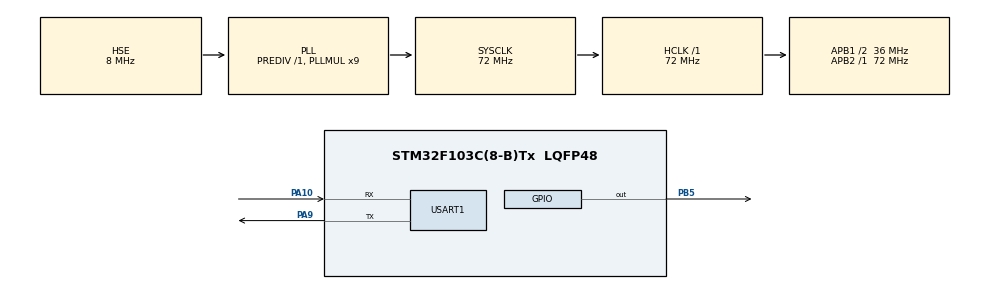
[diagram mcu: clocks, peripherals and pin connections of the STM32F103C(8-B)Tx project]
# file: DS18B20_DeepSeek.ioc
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Mcu.Family=STM32F1
Mcu.Name=STM32F103C(8-B)Tx
Mcu.Package=LQFP48
NVIC.PriorityGroup=NVIC_PRIORITYGROUP_4
PA10.Mode=Asynchronous
PA10.Signal=USART1_RX
PA13.Mode=Serial_Wire
PA13.Signal=SYS_JTMS-SWDIO
PA14.Mode=Serial_Wire
PA14.Signal=SYS_JTCK-SWCLK
PA9.Mode=Asynchronous
PA9.Signal=USART1_TX
PB5.GPIO_ModeDefaultOutputPP=GPIO_MODE_OUTPUT_OD
PB5.GPIO_PuPd=GPIO_NOPULL
PB5.Signal=GPIO_Output
PD0-OSC_IN.Mode=HSE-External-Oscillator
PD0-OSC_IN.Signal=RCC_OSC_IN
PD1-OSC_OUT.Mode=HSE-External-Oscillator
PD1-OSC_OUT.Signal=RCC_OSC_OUT
ProjectManager.HeapSize=0x200
ProjectManager.StackSize=0x400
ProjectManager.TargetToolchain=STM32CubeIDE
RCC.AHBFreq_Value=72000000
RCC.APB1CLKDivider=RCC_HCLK_DIV2
RCC.APB1Freq_Value=36000000
RCC.APB1TimFreq_Value=72000000
RCC.APB2Freq_Value=72000000
RCC.APB2TimFreq_Value=72000000
RCC.HCLKFreq_Value=72000000
RCC.PLLMUL=RCC_PLL_MUL9
RCC.PLLSourceVirtual=RCC_PLLSOURCE_HSE
RCC.SYSCLKFreq_VALUE=72000000
RCC.SYSCLKSource=RCC_SYSCLKSOURCE_PLLCLK
RCC.USBFreq_Value=72000000
USART1.VirtualMode=VM_ASYNC
board=custom

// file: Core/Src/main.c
/* USER CODE BEGIN Header */
/**
  * @file    main.c
  * @brief   Minimal firmware entry: HAL init + cooperative scheduler loop only.
  *
  * @details
  * This project is intentionally wired as a **standalone scheduler**:
  * no application tasks are registered here. USART1 is initialised so you can
  * optionally call scheduler_set_debug_uart() and scheduler_print_status() for
  * diagnostics (see scheduler.h and the guide at the top of scheduler.c).
  *
  * HARDWARE (typical Blue Pill):
  *   - MCU: STM32F103C8
  *   - UART: USART1 (PA9 TX, PA10 RX), 115200 8N1 — pins configured in HAL_UART_MspInit()
  *
  * TIME BASE:
  *   - SysTick drives HAL_GetTick() at 1 ms; the scheduler relies on that (see SCHEDULER_TICK_MS).
  */
/* USER CODE END Header */
#include "main.h"

/* USER CODE BEGIN Includes */
#include "scheduler.h"
/* USER CODE END Includes */

UART_HandleTypeDef huart1;

void SystemClock_Config(void);
static void MX_GPIO_Init(void);
static void MX_USART1_UART_Init(void);
/* USER CODE BEGIN PFP */
void Error_Handler(void);
/* USER CODE END PFP */

int main(void)
{

  /* MCU Configuration--------------------------------------------------------*/

  /* Reset of all peripherals, Initializes the Flash interface and the Systick. */
HAL_Init();

  /* Configure the system clock */
  SystemClock_Config();

  /* Initialize all configured peripherals */
  MX_GPIO_Init();
  MX_USART1_UART_Init();

  /* USER CODE BEGIN 2 */

  scheduler_init();
  /* Optional: enable scheduler_print_status() output on USART1 */
  scheduler_set_debug_uart(&huart1);

  /*
   * -------------------------------------------------------------------------
   * Register your application tasks here (see scheduler.h, section
   * "HOW TO ADD APPLICATION TASKS").
   * Example (commented out — requires your task module):
   *
   *   my_task_init();
   *   if (scheduler_add_task(my_task_run, 100U, TASK_MODE_PERIODIC_T, "MyTask") != SCH_STATUS_OK_T)
   *   {
   *       Error_Handler();
   *   }
   * -------------------------------------------------------------------------
   */

  /* USER CODE END 2 */

  /* Infinite loop */
  /* USER CODE BEGIN WHILE */
  while (1)
  {

      scheduler_run();
    /* USER CODE END WHILE */

  }
}

void SystemClock_Config(void)
{
  RCC_OscInitTypeDef RCC_OscInitStruct = {0};
  RCC_ClkInitTypeDef RCC_ClkInitStruct = {0};

  /** Initializes the RCC Oscillators according to the specified parameters
  * in the RCC_OscInitTypeDef structure.
  */
  RCC_OscInitStruct.OscillatorType = RCC_OSCILLATORTYPE_HSE;
  RCC_OscInitStruct.HSEState = RCC_HSE_ON;
  RCC_OscInitStruct.HSEPredivValue = RCC_HSE_PREDIV_DIV1;
  RCC_OscInitStruct.HSIState = RCC_HSI_ON;
  RCC_OscInitStruct.PLL.PLLState = RCC_PLL_ON;
  RCC_OscInitStruct.PLL.PLLSource = RCC_PLLSOURCE_HSE;
  RCC_OscInitStruct.PLL.PLLMUL = RCC_PLL_MUL9;
  if (HAL_RCC_OscConfig(&RCC_OscInitStruct) != HAL_OK)
  {
    Error_Handler();
  }

  /** Initializes the CPU, AHB and APB buses clocks
  */
  RCC_ClkInitStruct.ClockType = RCC_CLOCKTYPE_HCLK|RCC_CLOCKTYPE_SYSCLK
                              |RCC_CLOCKTYPE_PCLK1|RCC_CLOCKTYPE_PCLK2;
  RCC_ClkInitStruct.SYSCLKSource = RCC_SYSCLKSOURCE_PLLCLK;
  RCC_ClkInitStruct.AHBCLKDivider = RCC_SYSCLK_DIV1;
  RCC_ClkInitStruct.APB1CLKDivider = RCC_HCLK_DIV2;
  RCC_ClkInitStruct.APB2CLKDivider = RCC_HCLK_DIV1;

  if (HAL_RCC_ClockConfig(&RCC_ClkInitStruct, FLASH_LATENCY_2) != HAL_OK)
  {
    Error_Handler();
  }
}

static void MX_USART1_UART_Init(void)
{

  huart1.Instance = USART1;
  huart1.Init.BaudRate = 115200;
  huart1.Init.WordLength = UART_WORDLENGTH_8B;
  huart1.Init.StopBits = UART_STOPBITS_1;
  huart1.Init.Parity = UART_PARITY_NONE;
  huart1.Init.Mode = UART_MODE_TX_RX;
  huart1.Init.HwFlowCtl = UART_HWCONTROL_NONE;
  huart1.Init.OverSampling = UART_OVERSAMPLING_16;
  if (HAL_UART_Init(&huart1) != HAL_OK)
  {
    Error_Handler();
  }

}

static void MX_GPIO_Init(void)
{

  /*
   * Scheduler-only build: no application pins here.
   * USART1 (PA9/PA10) is configured in HAL_UART_MspInit() when UART is used.
   * Add your own GPIO_Init code in the USER CODE sections when you attach hardware.
   */

}

void Error_Handler(void)
{
  __disable_irq();
  while (1)
  {
  }
}
